# RX64M_BSC_Pilot register map
File version: 1.0
RX64M_BSC_Pilot peripheral registers generated from iodefine.h (pilot).
Registers are 16-bit, read-write, reset 0x0 unless marked. A register's access mark holds for its fields unless they carry their own. Offsets are from the block's base; lines under a group give offsets from that group; [hi:lo] are bit positions; {n}, {i} and the like mark numbered series; 'fields as' and 'values as' point back to an identical list; <NAME> marks a mode.

## Memory map
0x00081300 BSC size 0x2951

## BSC
Base 0x00081300
0x00 BERCLR 8-bit
  [0] STSCLR
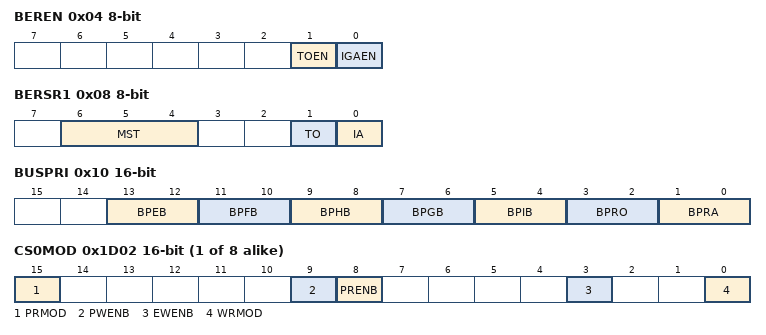
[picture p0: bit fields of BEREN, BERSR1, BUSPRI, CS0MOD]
0x04 BEREN 8-bit
  [1] TOEN, [0] IGAEN
0x08 BERSR1 8-bit ro
  [6:4] MST, [1] TO, [0] IA
0x0A BERSR2 ro
  [15:3] ADDR
0x10 BUSPRI
  [13:12] BPEB, [11:10] BPFB, [9:8] BPHB, [7:6] BPGB, [5:4] BPIB, [3:2] BPRO, [1:0] BPRA
{0x1D02+0x10*i} CS{i}MOD (i=0..7)
  [15] PRMOD, [9] PWENB, [8] PRENB, [3] EWENB, [0] WRMOD
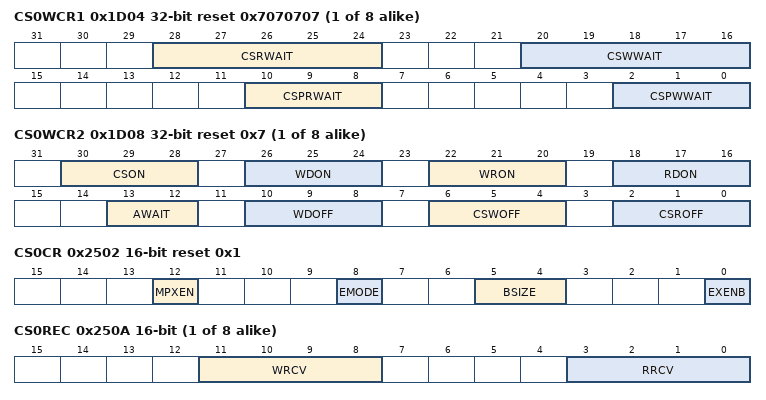
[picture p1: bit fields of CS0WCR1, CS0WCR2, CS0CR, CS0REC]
{0x1D04+0x10*i} CS{i}WCR1 32-bit reset 0x7070707 (i=0..7)
  [28:24] CSRWAIT, [20:16] CSWWAIT, [10:8] CSPRWAIT, [2:0] CSPWWAIT
{0x1D08+0x10*i} CS{i}WCR2 32-bit reset 0x7 (i=0..7)
  [30:28] CSON, [26:24] WDON, [22:20] WRON, [18:16] RDON, [13:12] AWAIT, [10:8] WDOFF, [6:4] CSWOFF, [2:0] CSROFF
0x2502 CS0CR reset 0x1 (reset mask 0xFFCF)
  [12] MPXEN, [8] EMODE, [5:4] BSIZE, [0] EXENB
{0x250A+0x10*i} CS{i}REC (i=0..7)
  [11:8] WRCV, [3:0] RRCV
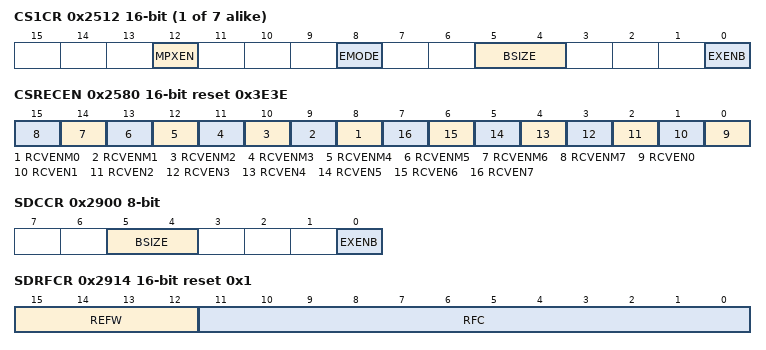
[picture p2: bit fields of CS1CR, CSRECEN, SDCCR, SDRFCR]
{0x2502+0x10*i} CS{i}CR (i=1..7)
  [12] MPXEN, [8] EMODE, [5:4] BSIZE, [0] EXENB
0x2580 CSRECEN reset 0x3E3E
  [n+8] RCVENM{n} (n=0..7), [n] RCVEN{n} (n=0..7)
0x2900 SDCCR 8-bit
  [5:4] BSIZE, [0] EXENB
0x2901 SDCMOD 8-bit
  [0] EMODE
0x2902 SDAMOD 8-bit
  [0] BE
0x2910 SDSELF 8-bit
  [0] SFEN
0x2914 SDRFCR reset 0x1
  [15:12] REFW, [11:0] RFC
0x2916 SDRFEN 8-bit
  [0] RFEN
0x2920 SDICR 8-bit
  [0] INIRQ
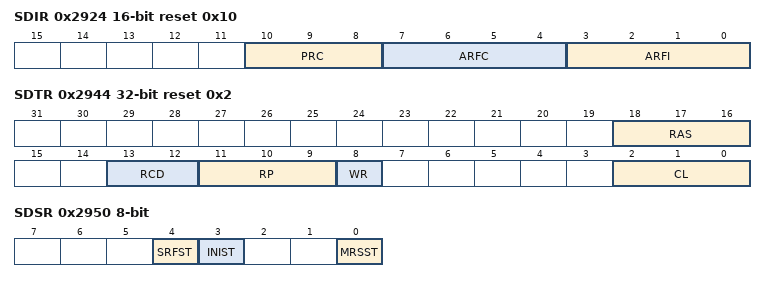
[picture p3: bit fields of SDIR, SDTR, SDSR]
0x2924 SDIR reset 0x10
  [10:8] PRC, [7:4] ARFC, [3:0] ARFI
0x2940 SDADR 8-bit
  [1:0] MXC
0x2944 SDTR 32-bit reset 0x2
  [18:16] RAS, [13:12] RCD, [11:9] RP, [8] WR, [2:0] CL
0x2948 SDMOD
  [14:0] MR
0x2950 SDSR 8-bit
  [4] SRFST, [3] INIST, [0] MRSST
